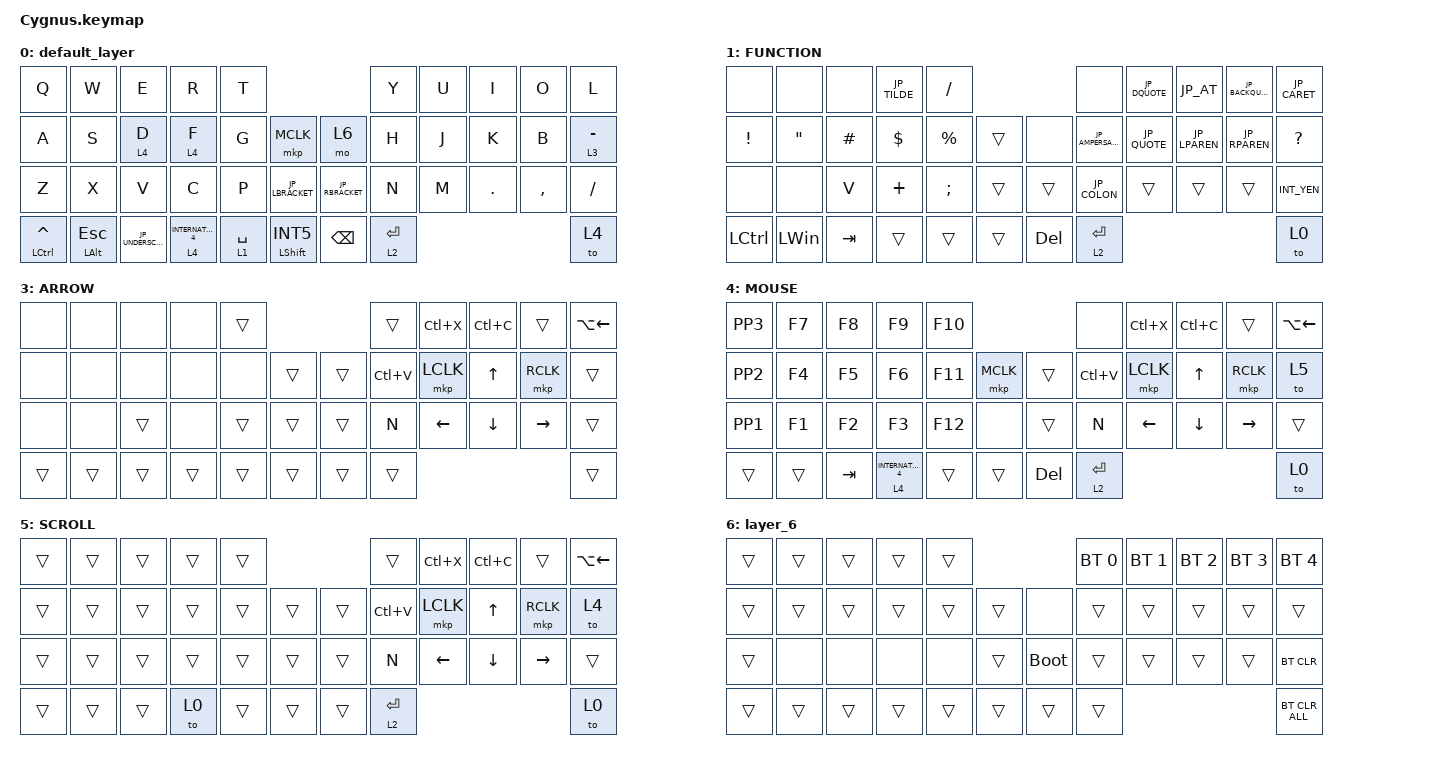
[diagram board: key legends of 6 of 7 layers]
#define ZMK_POINTING_DEFAULT_SCRL_VAL 120    // default: 10

#include <behaviors.dtsi>
#include <dt-bindings/zmk/bt.h>
#include <dt-bindings/zmk/keys.h>
#include <dt-bindings/zmk/pointing.h>

#define JP_DQUOTE       AT                // "　鈴木記入ここから
#define JP_AMPERSAND    CARET             // &
#define JP_QUOTE        AMPERSAND         // '
#define JP_EQUAL        UNDER             // =
#define JP_CARET        EQUAL             // ^
#define JP_YEN          0x89              // ¥
#define JP_PLUS         COLON             // +
#define JP_TILDE        PLUS              // ~
#define JP_PIPE         LS(0x89)          // |
#define JP_AT           LEFT_BRACKET      // @
#define JP_COLON        SINGLE_QUOTE      // :
#define JP_ASTERISK     DOUBLE_QUOTES     // *
#define JP_BACKQUOTE    LEFT_BRACE        // `
#define JP_UNDERSCORE   LS(0x87)          // _
#define JP_LBRACKET     RIGHT_BRACKET     // [
#define JP_RBRACKET     BACKSLASH         // ]
#define JP_LPAREN       ASTERISK          // (
#define JP_RPAREN       LEFT_PARENTHESIS  // )
#define JP_LBRACE       RIGHT_BRACE       // {
#define JP_RBRACE       PIPE              // }
#define JP_KANA         LANGUAGE_1       // かな
#define JP_EISU         LANGUAGE_2        // 英数
#define JP_HANZEN       GRAVE             // 半角/全角　鈴木記入ここまで
#define ZMK_MOUSE_DEFAULT_SCRL_VAL 25
#define MOUSE 4
#define SCROLL 5
#define NUM 6

&mt {
    flavor = "balanced";
    quick-tap-ms = <0>;
};

/ {
    combos {
        compatible = "zmk,combos";

        double_quotation {
            bindings = <&kp DQT>;
            key-positions = <20 21>;
        };
    };

    macros {
        PP1: to_layer_0 {
            compatible = "zmk,behavior-macro";
            #binding-cells = <0>;
            bindings = <&kp S &kp S &kp N0 &kp N0 &kp N1 &kp C &kp K &kp N1>;
            label = "PP1";
        };

        PP2: PP2 {
            compatible = "zmk,behavior-macro";
            #binding-cells = <0>;
            bindings = <&kp LS(S) &kp S &kp N0 &kp N0 &kp N1 &kp C &kp K &kp N1>;
            label = "PP2";
        };

        PP3: PP3 {
            compatible = "zmk,behavior-macro";
            #binding-cells = <0>;
            bindings = <&kp LS(S) &kp LS(S) &kp N0 &kp N0 &kp N1 &kp C &kp K &kp N1 &kp N1>;
            label = "PP3";
        };
    };

    behaviors {
        lt_to_layer_0: lt_to_layer_0 {
            compatible = "zmk,behavior-hold-tap";
            label = "LAYER_TAP_TO_0";
            bindings = <&mo>, <&PP1>;

            #binding-cells = <2>;
            tapping-term-ms = <200>;
        };


    rotate: rotate {
            compatible = "zmk,behavior-sensor-rotate";
            label = "ROTATE";

            #sensor-binding-cells = <0>;
            bindings = <&msc SCRL_UP>, <&msc SCRL_DOWN>;

            tap-ms = <20>;

        };
    };

    keymap {
        compatible = "zmk,keymap";

        default_layer {
            bindings = <
&kp Q                   &kp W                &kp E              &kp R                  &kp T                                                  &kp Y        &kp U  &kp I       &kp O      &kp L
&kp A                   &kp S                &lt 4 D            &lt 4 F                &kp G        &mkp MCLK                &mo 6            &kp H        &kp J  &kp K       &kp B      &lt 3 MINUS
&kp Z                   &kp X                &kp V              &kp C                  &kp P        &kp JP_LBRACKET          &kp JP_RBRACKET  &kp N        &kp M  &kp PERIOD  &kp COMMA  &kp SLASH
&mt LEFT_CONTROL CARET  &mt LEFT_ALT ESCAPE  &kp JP_UNDERSCORE  &lt 4 INTERNATIONAL_4  &lt 1 SPACE  &mt LEFT_SHIFT INT5      &kp BACKSPACE    &lt 2 ENTER                                &to 4
            >;

            sensor-bindings = <&inc_dec_kp PAGE_DOWN PAGE_UP>;
        };

        FUNCTION {
            bindings = <
&none            &none              &none     &kp JP_TILDE  &kp SLASH                              &none             &kp JP_DQUOTE  &kp JP_AT      &kp JP_BACKQUOTE  &kp JP_CARET
&kp EXCLAMATION  &kp DOUBLE_QUOTES  &kp HASH  &kp DOLLAR    &kp PERCENT    &trans      &none       &kp JP_AMPERSAND  &kp JP_QUOTE   &kp JP_LPAREN  &kp JP_RPAREN     &kp QUESTION
&none            &none              &kp V     &kp PLUS      &kp SEMICOLON  &trans      &trans      &kp JP_COLON      &trans         &trans         &trans            &kp INT_YEN
&kp LCTRL        &kp LEFT_WIN       &kp TAB   &trans        &trans         &trans      &kp DELETE  &lt 2 ENTER                                                       &to 0
            >;
        };

        NUM {
            bindings = <
&kp SLASH        &kp N7   &kp N8  &kp N9  &kp SLASH                              &kp SLASH        &kp N7  &kp N8  &kp N9  &kp SLASH
&kp JP_ASTERISK  &kp N4   &kp N5  &kp N6  &kp N0      &none       &none          &kp JP_ASTERISK  &kp N4  &kp N5  &kp N6  &kp N0
&kp MINUS        &kp N1   &kp N2  &kp N3  &kp PERIOD  &none       &kp JP_PLUS    &kp MINUS        &kp N1  &kp N2  &kp N3  &kp PERIOD
&kp JP_PLUS      &kp TAB  &trans  &trans  &trans      &trans      &kp BACKSPACE  &lt 2 ENTER
            >;

            sensor-bindings = <&inc_dec_kp LC(PAGE_UP) LC(PAGE_DOWN)>;
        };

        ARROW {
            bindings = <
&none   &none   &none   &none   &trans                      &trans     &kp LC(X)  &kp LC(C)  &trans     &kp LA(LEFT)
&none   &none   &none   &none   &none   &trans      &trans  &kp LC(V)  &mkp LCLK  &kp UP     &mkp RCLK  &trans
&none   &none   &trans  &none   &trans  &trans      &trans  &kp N      &kp LEFT   &kp DOWN   &kp RIGHT  &trans
&trans  &trans  &trans  &trans  &trans  &trans      &trans  &trans                                      &trans
            >;

            sensor-bindings = <&inc_dec_kp LC(PAGE_UP) LC(PAGE_DOWN)>;
        };

        MOUSE {
            bindings = <
&PP3    &kp F7  &kp F8   &kp F9                 &kp F10                             &none        &kp LC(X)       &kp LC(C)       &trans     &kp LA(LEFT)
&PP2    &kp F4  &kp F5   &kp F6                 &kp F11  &mkp MCLK      &trans      &kp LC(V)    &mkp LCLK       &kp UP_ARROW    &mkp RCLK  &to 5
&PP1    &kp F1  &kp F2   &kp F3                 &kp F12  &none          &trans      &kp N        &kp LEFT_ARROW  &kp DOWN_ARROW  &kp RIGHT  &trans
&trans  &trans  &kp TAB  &lt 4 INTERNATIONAL_4  &trans   &trans         &kp DELETE  &lt 2 ENTER                                             &to 0
            >;

            sensor-bindings = <&rotate>;
        };

        SCROLL {
            bindings = <
&trans  &trans  &trans  &trans  &trans                      &trans       &kp LC(X)  &kp LC(C)  &trans     &kp LA(LEFT_ARROW)
&trans  &trans  &trans  &trans  &trans  &trans      &trans  &kp LC(V)    &mkp LCLK  &kp UP     &mkp RCLK  &to 4
&trans  &trans  &trans  &trans  &trans  &trans      &trans  &kp N        &kp LEFT   &kp DOWN   &kp RIGHT  &trans
&trans  &trans  &trans  &to 0   &trans  &trans      &trans  &lt 2 ENTER                                   &to 0
            >;

            sensor-bindings = <&rotate>;
        };

        layer_6 {
            bindings = <
&trans  &trans  &trans  &trans  &trans                           &bt BT_SEL 0  &bt BT_SEL 1  &bt BT_SEL 2  &bt BT_SEL 3  &bt BT_SEL 4
&trans  &trans  &trans  &trans  &trans  &trans      &none        &trans        &trans        &trans        &trans        &trans
&trans  &none   &none   &none   &none   &trans      &bootloader  &trans        &trans        &trans        &trans        &bt BT_CLR
&trans  &trans  &trans  &trans  &trans  &trans      &trans       &trans                                                  &bt BT_CLR_ALL
            >;
        };
    };
};
